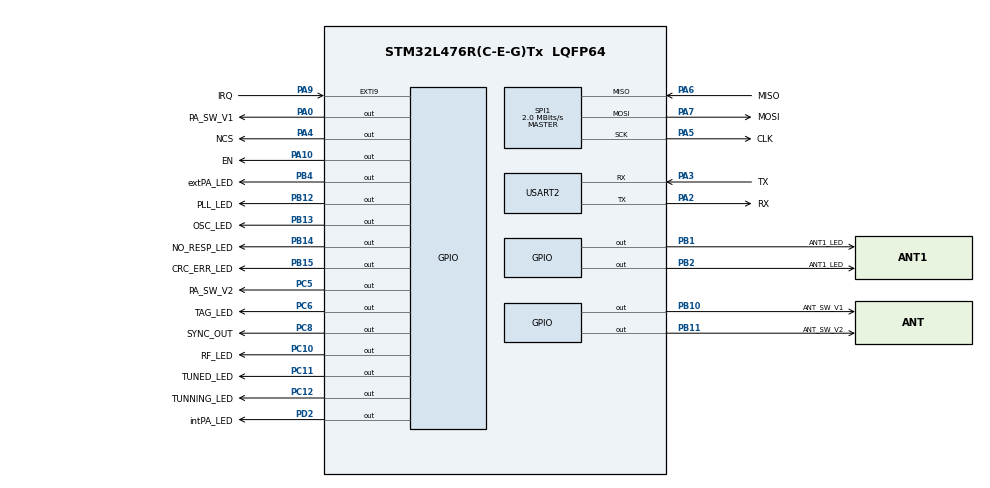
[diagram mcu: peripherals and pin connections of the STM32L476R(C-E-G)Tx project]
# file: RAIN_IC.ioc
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Mcu.Family=STM32L4
Mcu.Name=STM32L476R(C-E-G)Tx
Mcu.Package=LQFP64
NVIC.EXTI9_5_IRQn=true\:0\:0\:false\:false\:true\:true\:true
NVIC.PriorityGroup=NVIC_PRIORITYGROUP_4
PA0.GPIO_Label=PA_SW_V1
PA0.Signal=GPIO_Output
PA10.GPIO_Label=EN
PA10.Signal=GPIO_Output
PA13\ (JTMS-SWDIO).Mode=JTAG_4_pins
PA13\ (JTMS-SWDIO).Signal=SYS_JTMS-SWDIO
PA14\ (JTCK-SWCLK).Mode=JTAG_4_pins
PA14\ (JTCK-SWCLK).Signal=SYS_JTCK-SWCLK
PA15\ (JTDI).Mode=JTAG_4_pins
PA15\ (JTDI).Signal=SYS_JTDI
PA2.GPIO_Label=RX
PA2.Mode=Asynchronous
PA2.Signal=USART2_TX
PA3.GPIO_Label=TX
PA3.Mode=Asynchronous
PA3.Signal=USART2_RX
PA4.GPIO_Label=NCS
PA4.Signal=GPIO_Output
PA5.GPIO_Label=CLK
PA5.Mode=Full_Duplex_Master
PA5.Signal=SPI1_SCK
PA6.GPIO_Label=MISO
PA6.Mode=Full_Duplex_Master
PA6.Signal=SPI1_MISO
PA7.GPIO_Label=MOSI
PA7.Mode=Full_Duplex_Master
PA7.Signal=SPI1_MOSI
PA9.GPIO_Label=IRQ
PA9.Signal=GPXTI9
PB1.GPIO_Label=ANT1_LED
PB1.Signal=GPIO_Output
PB10.GPIO_Label=ANT_SW_V1
PB10.Signal=GPIO_Output
PB11.GPIO_Label=ANT_SW_V2
PB11.Signal=GPIO_Output
PB12.GPIO_Label=PLL_LED
PB12.Signal=GPIO_Output
PB13.GPIO_Label=OSC_LED
PB13.Signal=GPIO_Output
PB14.GPIO_Label=NO_RESP_LED
PB14.Signal=GPIO_Output
PB15.GPIO_Label=CRC_ERR_LED
PB15.Signal=GPIO_Output
PB2.GPIO_Label=ANT1_LED
PB2.Signal=GPIO_Output
PB3\ (JTDO-TRACESWO).Mode=JTAG_4_pins
PB3\ (JTDO-TRACESWO).Signal=SYS_JTDO-SWO
PB4\ (NJTRST).GPIO_Label=extPA_LED
PB4\ (NJTRST).Signal=GPIO_Output
PC10.GPIO_Label=RF_LED
PC10.Signal=GPIO_Output
PC11.GPIO_Label=TUNED_LED
PC11.Signal=GPIO_Output
PC12.GPIO_Label=TUNNING_LED
PC12.Signal=GPIO_Output
PC5.GPIO_Label=PA_SW_V2
PC5.Signal=GPIO_Output
PC6.GPIO_Label=TAG_LED
PC6.Signal=GPIO_Output
PC8.GPIO_Label=SYNC_OUT
PC8.Signal=GPIO_Output
PD2.GPIO_Label=intPA_LED
PD2.Signal=GPIO_Output
ProjectManager.HeapSize=0x200
ProjectManager.StackSize=0x400
ProjectManager.TargetToolchain=STM32CubeIDE
RCC.HSE_VALUE=8000000
RCC.HSI_VALUE=16000000
RCC.LSE_VALUE=32768
RCC.MSI_VALUE=4000000
RCC.VCOOutputFreq_Value=32000000
SPI1.CalculateBaudRate=2.0 MBits/s
SPI1.DataSize=SPI_DATASIZE_16BIT
SPI1.Direction=SPI_DIRECTION_2LINES
SPI1.Mode=SPI_MODE_MASTER
SPI1.VirtualType=VM_MASTER
USART2.VirtualMode-Asynchronous=VM_ASYNC
board=custom

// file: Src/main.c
/* USER CODE BEGIN Header */
/**
  ******************************************************************************
  * @file           : main.c
  * @brief          : Main program body
  ******************************************************************************
  * @attention
  *
  * <h2><center>&copy; Copyright (c) 2020 STMicroelectronics.
  * All rights reserved.</center></h2>
  *
  * This software component is licensed by ST under BSD 3-Clause license,
  * the "License"; You may not use this file except in compliance with the
  * License. You may obtain a copy of the License at:
  *                        opensource.org/licenses/BSD-3-Clause
  *
  ******************************************************************************
  */
/* USER CODE END Header */

#include "main.h"

SPI_HandleTypeDef hspi1;

UART_HandleTypeDef huart2;

/* USER CODE BEGIN PV */
typedef unsigned char BYTE;    /* defined all necessary registers here correctly*/
BYTE RSSI_Reg = 0x6b;          /*RSSI Reg*/
BYTE enter_directmode = 0x81; /*send this via SPI enables direct mode, in direct mode the IC works as simple RF front end*/

uint8_t buffer_rx[1];
/* USER CODE END PV */

void SystemClock_Config(void);
static void MX_GPIO_Init(void);
static void MX_SPI1_Init(void);
static void MX_USART2_UART_Init(void);

int main(void)
{

  /* MCU Configuration--------------------------------------------------------*/

  /* Reset of all peripherals, Initializes the Flash interface and the Systick. */
  HAL_Init();

  /* Configure the system clock */
  SystemClock_Config();

  /* Initialize all configured peripherals */
  MX_GPIO_Init();
  MX_SPI1_Init();
  MX_USART2_UART_Init();
  /* USER CODE BEGIN 2 */
  HAL_GPIO_WritePin(GPIOA, GPIO_PIN_10 , GPIO_PIN_SET );
  HAL_GPIO_WritePin(GPIOA, GPIO_PIN_4, GPIO_PIN_SET);
  void direct_mode(){
        HAL_GPIO_WritePin(GPIOA,GPIO_PIN_4, GPIO_PIN_RESET);
        HAL_Delay(20);
        HAL_SPI_Transmit(&hspi1, enter_directmode, 1, 10); /*enters the direct mode*/
        HAL_Delay(20);
        HAL_GPIO_WritePin(GPIOA,GPIO_PIN_4, GPIO_PIN_SET);
         }

  GPIO_PinState ISG = HAL_GPIO_ReadPin(GPIOA, GPIO_PIN_9);
  uint8_t flag = 0; /*whether this node has gone into direct mode or not;*/
  /* USER CODE END 2 */

  /* Infinite loop */
  /* USER CODE BEGIN WHILE */
  while (1)
  {

           /* Infinite loop */
           /* USER CODE BEGIN WHILE */
            if (flag != 0 && ISG ==SET){
                  direct_mode();
                  HAL_GPIO_WritePin(GPIOC, GPIO_PIN_8, GPIO_PIN_SET);
                  flag = 1;
            }

           }
}

void SystemClock_Config(void)
{
  RCC_OscInitTypeDef RCC_OscInitStruct = {0};
  RCC_ClkInitTypeDef RCC_ClkInitStruct = {0};
  RCC_PeriphCLKInitTypeDef PeriphClkInit = {0};

  /** Initializes the CPU, AHB and APB busses clocks
  */
  RCC_OscInitStruct.OscillatorType = RCC_OSCILLATORTYPE_MSI;
  RCC_OscInitStruct.MSIState = RCC_MSI_ON;
  RCC_OscInitStruct.MSICalibrationValue = 0;
  RCC_OscInitStruct.MSIClockRange = RCC_MSIRANGE_6;
  RCC_OscInitStruct.PLL.PLLState = RCC_PLL_NONE;
  if (HAL_RCC_OscConfig(&RCC_OscInitStruct) != HAL_OK)
  {
    Error_Handler();
  }
  /** Initializes the CPU, AHB and APB busses clocks
  */
  RCC_ClkInitStruct.ClockType = RCC_CLOCKTYPE_HCLK|RCC_CLOCKTYPE_SYSCLK
                              |RCC_CLOCKTYPE_PCLK1|RCC_CLOCKTYPE_PCLK2;
  RCC_ClkInitStruct.SYSCLKSource = RCC_SYSCLKSOURCE_MSI;
  RCC_ClkInitStruct.AHBCLKDivider = RCC_SYSCLK_DIV1;
  RCC_ClkInitStruct.APB1CLKDivider = RCC_HCLK_DIV1;
  RCC_ClkInitStruct.APB2CLKDivider = RCC_HCLK_DIV1;

  if (HAL_RCC_ClockConfig(&RCC_ClkInitStruct, FLASH_LATENCY_0) != HAL_OK)
  {
    Error_Handler();
  }
  PeriphClkInit.PeriphClockSelection = RCC_PERIPHCLK_USART2;
  PeriphClkInit.Usart2ClockSelection = RCC_USART2CLKSOURCE_PCLK1;
  if (HAL_RCCEx_PeriphCLKConfig(&PeriphClkInit) != HAL_OK)
  {
    Error_Handler();
  }
  /** Configure the main internal regulator output voltage
  */
  if (HAL_PWREx_ControlVoltageScaling(PWR_REGULATOR_VOLTAGE_SCALE1) != HAL_OK)
  {
    Error_Handler();
  }
}

static void MX_SPI1_Init(void)
{

  /* SPI1 parameter configuration*/
  hspi1.Instance = SPI1;
  hspi1.Init.Mode = SPI_MODE_MASTER;
  hspi1.Init.Direction = SPI_DIRECTION_2LINES;
  hspi1.Init.DataSize = SPI_DATASIZE_16BIT;
  hspi1.Init.CLKPolarity = SPI_POLARITY_LOW;
  hspi1.Init.CLKPhase = SPI_PHASE_1EDGE;
  hspi1.Init.NSS = SPI_NSS_SOFT;
  hspi1.Init.BaudRatePrescaler = SPI_BAUDRATEPRESCALER_2;
  hspi1.Init.FirstBit = SPI_FIRSTBIT_MSB;
  hspi1.Init.TIMode = SPI_TIMODE_DISABLE;
  hspi1.Init.CRCCalculation = SPI_CRCCALCULATION_DISABLE;
  hspi1.Init.CRCPolynomial = 7;
  hspi1.Init.CRCLength = SPI_CRC_LENGTH_DATASIZE;
  hspi1.Init.NSSPMode = SPI_NSS_PULSE_ENABLE;
  if (HAL_SPI_Init(&hspi1) != HAL_OK)
  {
    Error_Handler();
  }

}

static void MX_USART2_UART_Init(void)
{

  huart2.Instance = USART2;
  huart2.Init.BaudRate = 115200;
  huart2.Init.WordLength = UART_WORDLENGTH_8B;
  huart2.Init.StopBits = UART_STOPBITS_1;
  huart2.Init.Parity = UART_PARITY_NONE;
  huart2.Init.Mode = UART_MODE_TX_RX;
  huart2.Init.HwFlowCtl = UART_HWCONTROL_NONE;
  huart2.Init.OverSampling = UART_OVERSAMPLING_16;
  huart2.Init.OneBitSampling = UART_ONE_BIT_SAMPLE_DISABLE;
  huart2.AdvancedInit.AdvFeatureInit = UART_ADVFEATURE_NO_INIT;
  if (HAL_UART_Init(&huart2) != HAL_OK)
  {
    Error_Handler();
  }

}

static void MX_GPIO_Init(void)
{
  GPIO_InitTypeDef GPIO_InitStruct = {0};

  /* GPIO Ports Clock Enable */
  __HAL_RCC_GPIOA_CLK_ENABLE();
  __HAL_RCC_GPIOC_CLK_ENABLE();
  __HAL_RCC_GPIOB_CLK_ENABLE();
  __HAL_RCC_GPIOD_CLK_ENABLE();

  /*Configure GPIO pin Output Level */
  HAL_GPIO_WritePin(GPIOA, PA_SW_V1_Pin|NCS_Pin|EN_Pin, GPIO_PIN_RESET);

  /*Configure GPIO pin Output Level */
  HAL_GPIO_WritePin(GPIOC, PA_SW_V2_Pin|TAG_LED_Pin|SYNC_OUT_Pin|RF_LED_Pin
                          |TUNED_LED_Pin|TUNNING_LED_Pin, GPIO_PIN_RESET);

  /*Configure GPIO pin Output Level */
  HAL_GPIO_WritePin(GPIOB, ANT1_LED_Pin|ANT1_LEDB2_Pin|ANT_SW_V1_Pin|ANT_SW_V2_Pin
                          |PLL_LED_Pin|OSC_LED_Pin|NO_RESP_LED_Pin|CRC_ERR_LED_Pin
                          |extPA_LED_Pin, GPIO_PIN_RESET);

  /*Configure GPIO pin Output Level */
  HAL_GPIO_WritePin(intPA_LED_GPIO_Port, intPA_LED_Pin, GPIO_PIN_RESET);

  /*Configure GPIO pins : PA_SW_V1_Pin NCS_Pin EN_Pin */
  GPIO_InitStruct.Pin = PA_SW_V1_Pin|NCS_Pin|EN_Pin;
  GPIO_InitStruct.Mode = GPIO_MODE_OUTPUT_PP;
  GPIO_InitStruct.Pull = GPIO_NOPULL;
  GPIO_InitStruct.Speed = GPIO_SPEED_FREQ_LOW;
  HAL_GPIO_Init(GPIOA, &GPIO_InitStruct);

  /*Configure GPIO pins : PA_SW_V2_Pin TAG_LED_Pin SYNC_OUT_Pin RF_LED_Pin
                           TUNED_LED_Pin TUNNING_LED_Pin */
  GPIO_InitStruct.Pin = PA_SW_V2_Pin|TAG_LED_Pin|SYNC_OUT_Pin|RF_LED_Pin
                          |TUNED_LED_Pin|TUNNING_LED_Pin;
  GPIO_InitStruct.Mode = GPIO_MODE_OUTPUT_PP;
  GPIO_InitStruct.Pull = GPIO_NOPULL;
  GPIO_InitStruct.Speed = GPIO_SPEED_FREQ_LOW;
  HAL_GPIO_Init(GPIOC, &GPIO_InitStruct);

  /*Configure GPIO pins : ANT1_LED_Pin ANT1_LEDB2_Pin ANT_SW_V1_Pin ANT_SW_V2_Pin
                           PLL_LED_Pin OSC_LED_Pin NO_RESP_LED_Pin CRC_ERR_LED_Pin
                           extPA_LED_Pin */
  GPIO_InitStruct.Pin = ANT1_LED_Pin|ANT1_LEDB2_Pin|ANT_SW_V1_Pin|ANT_SW_V2_Pin
                          |PLL_LED_Pin|OSC_LED_Pin|NO_RESP_LED_Pin|CRC_ERR_LED_Pin
                          |extPA_LED_Pin;
  GPIO_InitStruct.Mode = GPIO_MODE_OUTPUT_PP;
  GPIO_InitStruct.Pull = GPIO_NOPULL;
  GPIO_InitStruct.Speed = GPIO_SPEED_FREQ_LOW;
  HAL_GPIO_Init(GPIOB, &GPIO_InitStruct);

  /*Configure GPIO pin : IRQ_Pin */
  GPIO_InitStruct.Pin = IRQ_Pin;
  GPIO_InitStruct.Mode = GPIO_MODE_IT_RISING;
  GPIO_InitStruct.Pull = GPIO_NOPULL;
  HAL_GPIO_Init(IRQ_GPIO_Port, &GPIO_InitStruct);

  /*Configure GPIO pin : intPA_LED_Pin */
  GPIO_InitStruct.Pin = intPA_LED_Pin;
  GPIO_InitStruct.Mode = GPIO_MODE_OUTPUT_PP;
  GPIO_InitStruct.Pull = GPIO_NOPULL;
  GPIO_InitStruct.Speed = GPIO_SPEED_FREQ_LOW;
  HAL_GPIO_Init(intPA_LED_GPIO_Port, &GPIO_InitStruct);

  /* EXTI interrupt init*/
  HAL_NVIC_SetPriority(EXTI9_5_IRQn, 0, 0);
  HAL_NVIC_EnableIRQ(EXTI9_5_IRQn);

}

void Error_Handler(void)
{
}

/************************ (C) COPYRIGHT STMicroelectronics *****END OF FILE****/
